# iostr750 register map
Registers from a debugger description file.
Registers are 16-bit, access not given, no defined reset value unless marked. A register's access mark holds for its fields unless they carry their own. Addresses are absolute; registers are grouped by the start of their names; lines under a group give offsets from that group; [hi:lo] are bit positions; {n}, {i} and the like mark numbered series; 'fields as' and 'values as' point back to an identical list; <NAME> marks a mode.

## MRCC
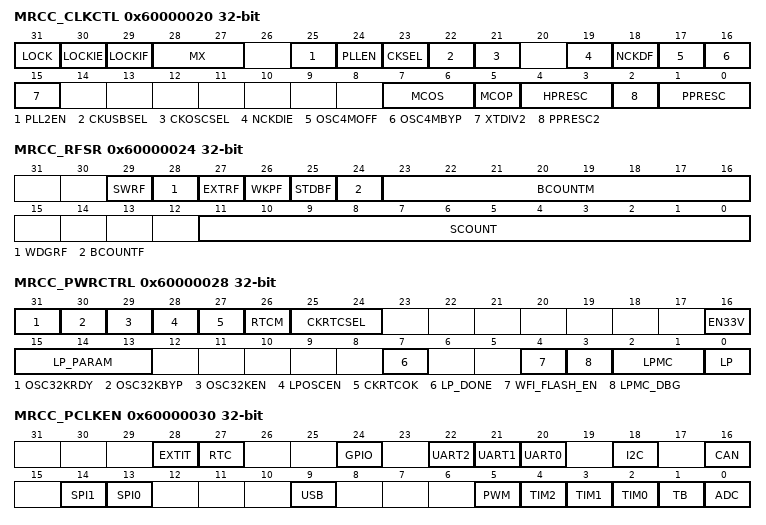
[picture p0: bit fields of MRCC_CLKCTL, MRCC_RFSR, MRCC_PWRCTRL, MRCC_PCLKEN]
0x60000020 MRCC_CLKCTL 32-bit
  [31] LOCK, [30] LOCKIE, [29] LOCKIF, [28:27] MX, [25] PLL2EN, [24] PLLEN, [23] CKSEL, [22] CKUSBSEL, [21] CKOSCSEL, [19] NCKDIE, [18] NCKDF, [17] OSC4MOFF, [16] OSC4MBYP, [15] XTDIV2, [7:6] MCOS, [5] MCOP, [4:3] HPRESC, [2] PPRESC2, [1:0] PPRESC
0x60000024 MRCC_RFSR 32-bit
  [29] SWRF, [28] WDGRF, [27] EXTRF, [26] WKPF, [25] STDBF, [24] BCOUNTF, [23:16] BCOUNTM, [11:0] SCOUNT
0x60000028 MRCC_PWRCTRL 32-bit
  [31] OSC32KRDY, [30] OSC32KBYP, [29] OSC32KEN, [28] LPOSCEN, [27] CKRTCOK, [26] RTCM, [25:24] CKRTCSEL, [16] EN33V, [15:13] LP_PARAM, [7] LP_DONE, [4] WFI_FLASH_EN, [3] LPMC_DBG, [2:1] LPMC, [0] LP
0x60000030 MRCC_PCLKEN 32-bit
  [28] EXTIT, [27] RTC, [24] GPIO, [22] UART2, [21] UART1, [20] UART0, [18] I2C, [16] CAN, [14] SPI1, [13] SPI0, [9] USB, [5] PWM, [4] TIM2, [3] TIM1, [2] TIM0, [1] TB, [0] ADC
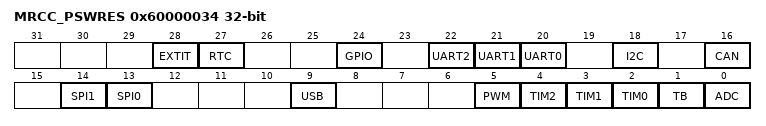
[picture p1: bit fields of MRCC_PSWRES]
0x60000034 MRCC_PSWRES 32-bit
  fields as MRCC_PCLKEN
0x60000040 MRCC_BKP0 32-bit
0x60000044 MRCC_BKP1 32-bit

## GPIO
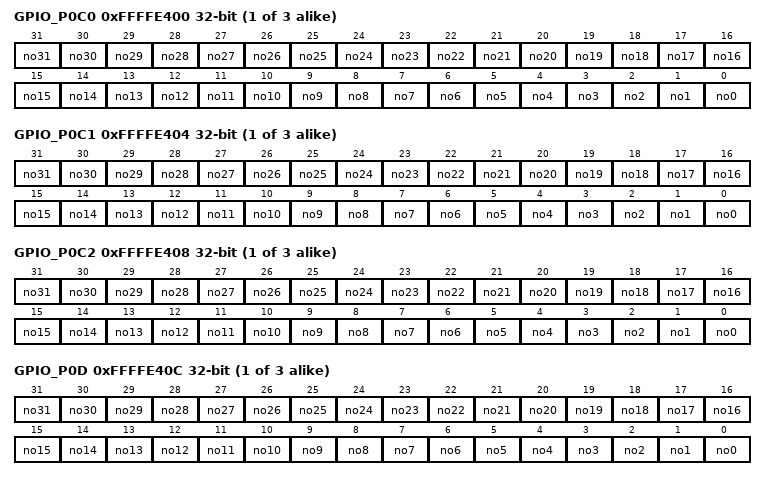
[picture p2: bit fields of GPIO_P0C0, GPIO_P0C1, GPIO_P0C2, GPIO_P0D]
{0xFFFFE400+0x40*i} GPIO_P{i}C0 32-bit (i=0..2)
  [n] no{n} (n=0..31)
{0xFFFFE404+0x40*i} GPIO_P{i}C1 32-bit (i=0..2)
  [n] no{n} (n=0..31)
{0xFFFFE408+0x40*i} GPIO_P{i}C2 32-bit (i=0..2)
  [n] no{n} (n=0..31)
{0xFFFFE40C+0x40*i} GPIO_P{i}D 32-bit (i=0..2)
  [n] no{n} (n=0..31)
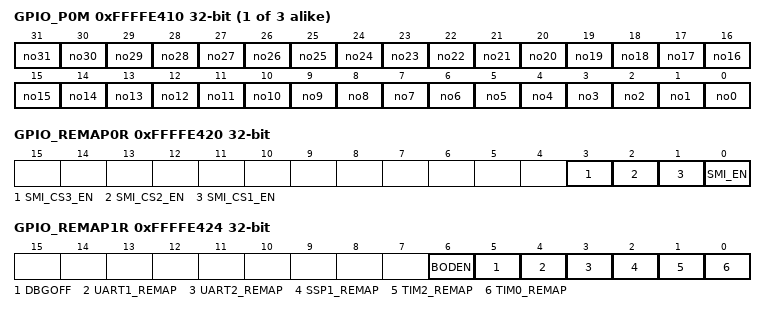
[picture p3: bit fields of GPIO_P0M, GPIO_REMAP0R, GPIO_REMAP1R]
{0xFFFFE410+0x40*i} GPIO_P{i}M 32-bit (i=0..2)
  [n] no{n} (n=0..31)
0xFFFFE420 GPIO_REMAP0R 32-bit
  [3] SMI_CS3_EN, [2] SMI_CS2_EN, [1] SMI_CS1_EN, [0] SMI_EN
0xFFFFE424 GPIO_REMAP1R 32-bit
  [6] BODEN, [5] DBGOFF, [4] UART1_REMAP, [3] UART2_REMAP, [2] SSP1_REMAP, [1] TIM2_REMAP, [0] TIM0_REMAP

## EIC
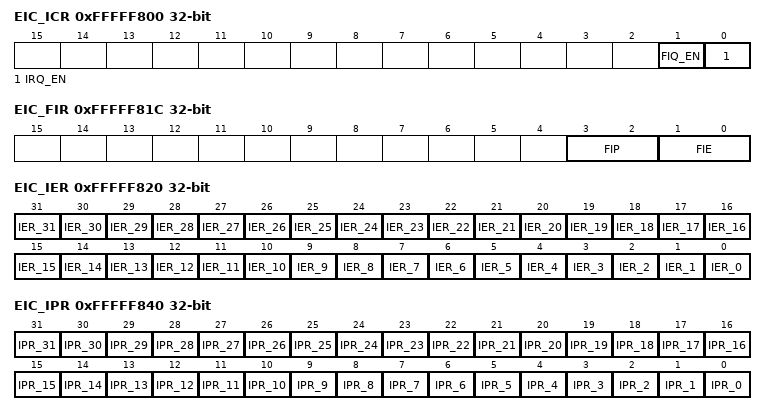
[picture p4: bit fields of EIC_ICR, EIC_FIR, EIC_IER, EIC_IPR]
0xFFFFF800 EIC_ICR 32-bit
  [1] FIQ_EN, [0] IRQ_EN
0xFFFFF804 EIC_CICR 32-bit
  [4:0] CIC
0xFFFFF808 EIC_CIPR 32-bit
  [3:0] CIP
0xFFFFF810 EIC_FIER 32-bit
  [1:0] FIE
0xFFFFF814 EIC_FIPR 32-bit
  [1:0] FIP
0xFFFFF818 EIC_IVR 32-bit
0xFFFFF81C EIC_FIR 32-bit
  [3:2] FIP, [1:0] FIE
0xFFFFF820 EIC_IER 32-bit
  [n] IER_{n} (n=0..31)
0xFFFFF840 EIC_IPR 32-bit
  [n] IPR_{n} (n=0..31)
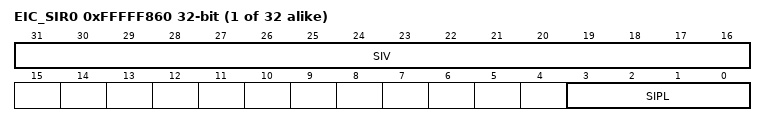
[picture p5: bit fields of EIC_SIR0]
{0xFFFFF860+4i} EIC_SIR{i} 32-bit (i=0..31)
  [31:16] SIV, [3:0] SIPL

## EXTIT
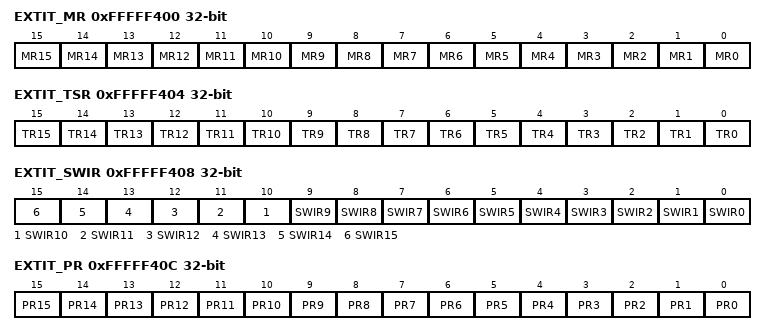
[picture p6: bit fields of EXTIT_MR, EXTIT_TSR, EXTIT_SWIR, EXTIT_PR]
0xFFFFF400 EXTIT_MR 32-bit
  [n] MR{n} (n=0..15)
0xFFFFF404 EXTIT_TSR 32-bit
  [n] TR{n} (n=0..15)
0xFFFFF408 EXTIT_SWIR 32-bit
  [n] SWIR{n} (n=0..15)
0xFFFFF40C EXTIT_PR 32-bit
  [n] PR{n} (n=0..15)

## DMA
{0xFFFFEC00+0x40*i} DMA_SOURCEL{i} (i=0..3)
{0xFFFFEC04+0x40*i} DMA_SOURCEH{i} (i=0..3)
{0xFFFFEC08+0x40*i} DMA_DESTL{i} (i=0..3)
{0xFFFFEC0C+0x40*i} DMA_DESTH{i} (i=0..3)
{0xFFFFEC10+0x40*i} DMA_MAX{i} (i=0..3)
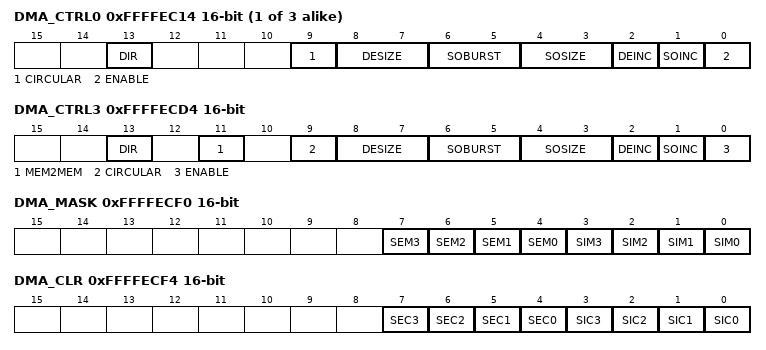
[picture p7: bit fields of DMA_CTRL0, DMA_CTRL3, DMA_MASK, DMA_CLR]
{0xFFFFEC14+0x40*i} DMA_CTRL{i} (i=0..2)
  [13] DIR, [9] CIRCULAR, [8:7] DESIZE, [6:5] SOBURST, [4:3] SOSIZE, [2] DEINC, [1] SOINC, [0] ENABLE
{0xFFFFEC18+0x40*i} DMA_SOCURRH{i} (i=0..3)
{0xFFFFEC1C+0x40*i} DMA_SOCURRL{i} (i=0..3)
{0xFFFFEC20+0x40*i} DMA_DECURRH{i} (i=0..3)
{0xFFFFEC24+0x40*i} DMA_DECURRL{i} (i=0..3)
{0xFFFFEC28+0x40*i} DMA_TCNT{i} (i=0..3)
{0xFFFFEC2C+0x40*i} DMA_LUBUFF{i} (i=0..3)
0xFFFFECD4 DMA_CTRL3
  [13] DIR, [11] MEM2MEM, [9] CIRCULAR, [8:7] DESIZE, [6:5] SOBURST, [4:3] SOSIZE, [2] DEINC, [1] SOINC, [0] ENABLE
0xFFFFECF0 DMA_MASK
  [n+4] SEM{n} (n=0..3), [n] SIM{n} (n=0..3)
0xFFFFECF4 DMA_CLR
  [n+4] SEC{n} (n=0..3), [n] SIC{n} (n=0..3)
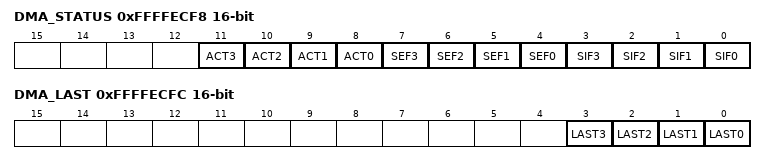
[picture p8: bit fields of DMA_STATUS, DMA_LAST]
0xFFFFECF8 DMA_STATUS
  [n+8] ACT{n} (n=0..3), [n+4] SEF{n} (n=0..3), [n] SIF{n} (n=0..3)
0xFFFFECFC DMA_LAST
  [n] LAST{n} (n=0..3)
